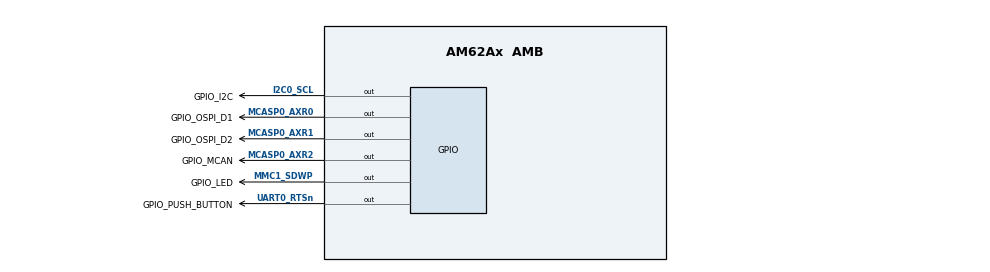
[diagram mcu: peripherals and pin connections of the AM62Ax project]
/**
 * @cliArgs --device "AM62Ax" --part "Default" --package "AMB" --context "a53ss0-0" --product "MCU_PLUS_SDK@07.03.01"
 * @versions {"tool":"1.26.2+4477"}
 */

/**
 * Import the modules used in this configuration.
 */
const gpio       = scripting.addModule("/drivers/gpio/gpio", {}, false);
const gpio1      = gpio.addInstance();
const gpio2      = gpio.addInstance();
const gpio3      = gpio.addInstance();
const gpio4      = gpio.addInstance();
const gpio5      = gpio.addInstance();
const gpio6      = gpio.addInstance();
const gpio7      = gpio.addInstance();
const gpio8      = gpio.addInstance();
const gpio9      = gpio.addInstance();
const gpio10     = gpio.addInstance();
const debug_log  = scripting.addModule("/kernel/dpl/debug_log");
const mmu_armv8  = scripting.addModule("/kernel/dpl/mmu_armv8", {}, false);
const mmu_armv81 = mmu_armv8.addInstance();
const mmu_armv82 = mmu_armv8.addInstance();
const mmu_armv83 = mmu_armv8.addInstance();

/**
 * Write custom configuration values to the imported modules.
 */
gpio1.$name                = "GPIO_LED";
gpio1.pinDir               = "OUTPUT";
gpio1.GPIO.gpioPin.$assign = "MMC1_SDWP";

gpio2.$name                = "GPIO_PUSH_BUTTON";
gpio2.trigType             = "RISE_EDGE";
gpio2.GPIO.gpioPin.$assign = "UART0_RTSn";

gpio3.$name                = "GPIO_I2C";
gpio3.pinDir               = "OUTPUT";
gpio3.trigType             = "FALL_EDGE";
gpio3.GPIO.gpioPin.$assign = "I2C0_SCL";

gpio4.$name                = "GPIO_MCAN";
gpio4.pinDir               = "OUTPUT";
gpio4.trigType             = "BOTH_EDGE";
gpio4.GPIO.gpioPin.$assign = "MCASP0_AXR2";

gpio5.$name                = "GPIO_OSPI_D1";
gpio5.pinDir               = "OUTPUT";
gpio5.trigType             = "RISE_EDGE";
gpio5.GPIO.gpioPin.$assign = "MCASP0_AXR0";

gpio6.$name                = "GPIO_OSPI_D2";
gpio6.pinDir               = "OUTPUT";
gpio6.trigType             = "FALL_EDGE";
gpio6.GPIO.gpioPin.$assign = "MCASP0_AXR1";

gpio7.$name    = "GPIO_INPUT";
gpio7.trigType = "RISE_EDGE";

gpio8.$name    = "GPIO_OUTPUT";
gpio8.pinDir   = "OUTPUT";
gpio8.trigType = "RISE_EDGE";

gpio9.$name = "CONFIG_GPIO0";

gpio10.$name = "CONFIG_GPIO1";

debug_log.enableUartLog        = true;
debug_log.uartLog.$name        = "CONFIG_UART_CONSOLE";
debug_log.uartLog.UART.$assign = "USART0";

mmu_armv81.size  = 0x80000000;
mmu_armv81.$name = "SOC_MEM_REGION";

mmu_armv82.vAddr     = 0x70000000;
mmu_armv82.pAddr     = 0x70000000;
mmu_armv82.size      = 0x200000;
mmu_armv82.attribute = "MAIR7";
mmu_armv82.$name     = "SHM_MEM_REGION";

mmu_armv83.vAddr     = 0x80000000;
mmu_armv83.pAddr     = 0x80000000;
mmu_armv83.size      = 0x80000000;
mmu_armv83.attribute = "MAIR7";
mmu_armv83.$name     = "DDR_REGION";

/**
 * Pinmux solution for unlocked pins/peripherals. This ensures that minor changes to the automatic solver in a future
 * version of the tool will not impact the pinmux you originally saw.  These lines can be completely deleted in order to
 * re-solve from scratch.
 */
gpio1.GPIO.$suggestSolution                 = "GPIO1";
gpio2.GPIO.$suggestSolution                 = "GPIO1";
gpio3.GPIO.$suggestSolution                 = "GPIO1";
gpio4.GPIO.$suggestSolution                 = "GPIO1";
gpio5.GPIO.$suggestSolution                 = "GPIO1";
gpio6.GPIO.$suggestSolution                 = "GPIO1";
gpio7.GPIO.$suggestSolution                 = "GPIO1";
gpio7.GPIO.gpioPin.$suggestSolution         = "USB1_DRVVBUS";
gpio8.GPIO.$suggestSolution                 = "GPIO1";
gpio8.GPIO.gpioPin.$suggestSolution         = "USB0_DRVVBUS";
gpio9.GPIO.$suggestSolution                 = "GPIO1";
gpio9.GPIO.gpioPin.$suggestSolution         = "MMC1_SDCD";
gpio10.GPIO.$suggestSolution                = "GPIO1";
gpio10.GPIO.gpioPin.$suggestSolution        = "RGMII2_TD3";
debug_log.uartLog.UART.RXD.$suggestSolution = "UART0_RXD";
debug_log.uartLog.UART.TXD.$suggestSolution = "UART0_TXD";
